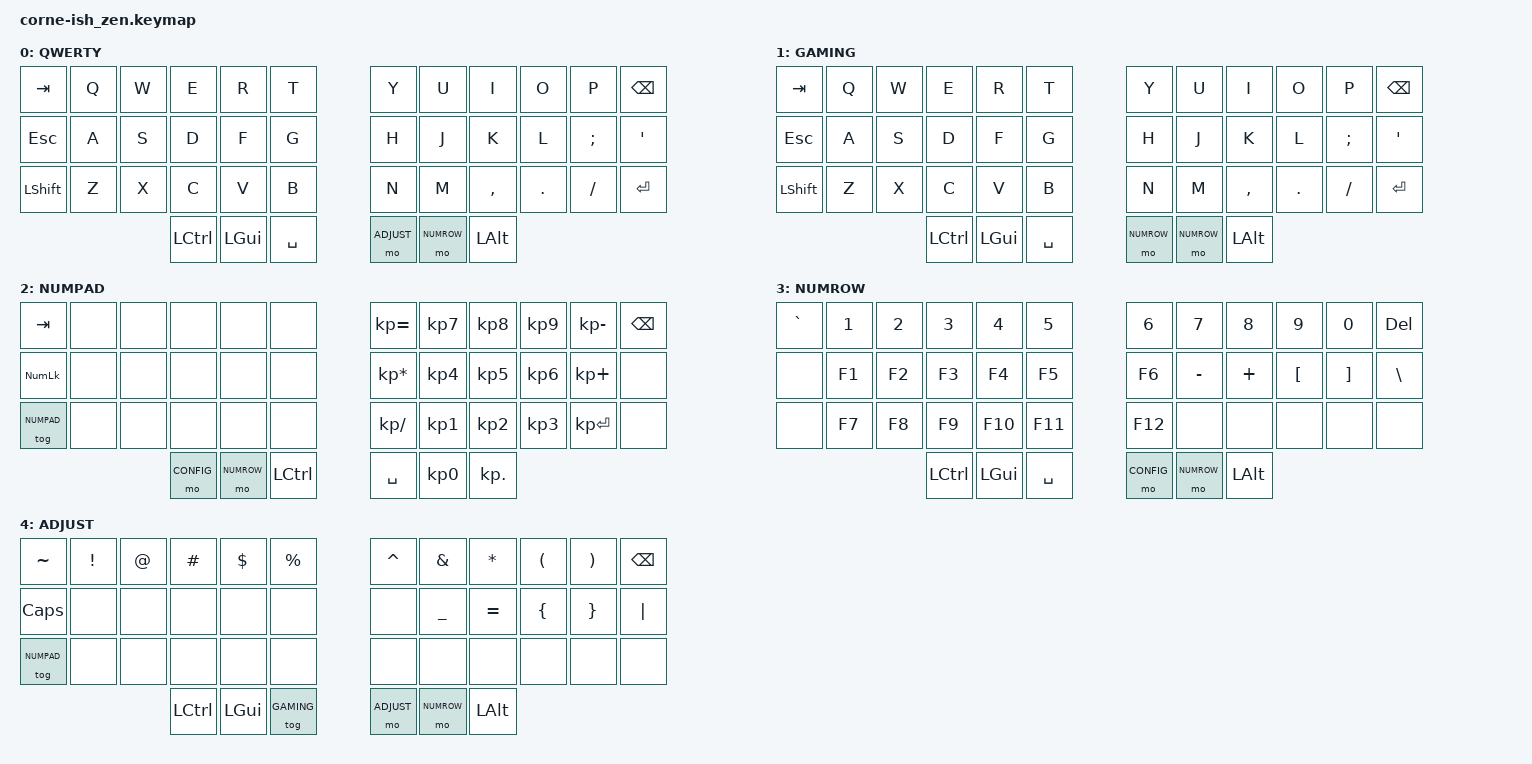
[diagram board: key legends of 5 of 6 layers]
/*
*
* Copyright (c) 2021 lowprokb.ca
* SPDX-License-Identifier: MIT
*
*/

#include <behaviors.dtsi>
#include <dt-bindings/zmk/keys.h>
#include <dt-bindings/zmk/bt.h>

#define QWERTY 0
#define GAMING 1
#define NUMPAD 2
#define NUMROW 3
#define ADJUST 4
#define CONFIG 5

/ {
        keymap {
                compatible = "zmk,keymap";

                default_layer {
                        label = "QWERTY";
                        bindings = <
   &kp TAB   &kp Q &kp W &kp E &kp R &kp T    &kp Y &kp U &kp I    &kp O   &kp P    &kp BKSP
   &kp ESC  &kp A &kp S &kp D &kp F &kp G    &kp H &kp J &kp K    &kp L   &kp SEMI &kp QUOT 
   &kp LSHFT &kp Z &kp X &kp C &kp V &kp B    &kp N &kp M &kp CMMA &kp DOT &kp FSLH &kp RETURN
              &kp LCTL &kp LGUI &kp SPC    &mo ADJUST &mo NUMROW &kp LALT
                        >;
                };

                gaming_layer {
                        label = "GAMING";
                        bindings = <
   &kp TAB   &kp Q &kp W &kp E &kp R &kp T    &kp Y &kp U &kp I    &kp O   &kp P    &kp BKSP
   &kp ESC  &kp A &kp S &kp D &kp F &kp G    &kp H &kp J &kp K    &kp L   &kp SEMI &kp QUOT 
   &kp LSHFT &kp Z &kp X &kp C &kp V &kp B    &kp N &kp M &kp CMMA &kp DOT &kp FSLH &kp RETURN
              &kp LCTL &kp LGUI &kp SPC    &mo NUMROW &mo NUMROW &kp LALT
                        >;
                };

                numpad_layer {
                        label = "NUMPAD";
                        bindings = < 
   &kp TAB     &none &none &none &none &none    &kp KP_EQUAL    &kp KP_N7 &kp KP_N8 &kp KP_N9 &kp KP_MINUS &kp BSPC
   &kp KP_NLCK &none &none &none &none &none    &kp KP_ASTERISK &kp KP_N4 &kp KP_N5 &kp KP_N6 &kp KP_PLUS  &none
   &tog NUMPAD &none &none &none &none &none    &kp KP_SLASH    &kp KP_N1 &kp KP_N2 &kp KP_N3 &kp KP_ENTER &none
              &mo CONFIG &mo NUMROW &kp LCTL   &kp SPC &kp KP_N0 &kp KP_DOT
                        >;
                };

                numrow_layer {
                        label = "NUMROW";
                        bindings = <
   &kp GRAVE &kp N1 &kp N2  &kp N3 &kp N4 &kp N5       &kp N6   &kp N7   &kp N8 &kp N9    &kp N0   &kp DEL
   &none     &kp F1  &kp F2 &kp F3 &kp F4 &kp F5    &kp F6 &kp MINUS &kp PLUS &kp LBKT &kp RBKT &kp BSLH
   &none     &kp F7  &kp F8 &kp F9 &kp F10  &kp F11     &kp F12    &none    &none  &none     &none    &none 
                          &kp LCTL &kp LGUI &kp SPACE    &mo CONFIG  &mo NUMROW &kp LALT

                        >;
                };

                adjust_layer {
                        label = "ADJUST";
                        bindings = <
   &kp TILDE   &kp EXCL  &kp AT   &kp POUND &kp DLLR &kp PRCNT    &kp CARET   &kp AMPS   &kp STAR &kp LPAR   &kp RPAR &kp BKSP
   &kp CAPS    &none  &none &none &none  &none     &none  &kp UNDER &kp EQUAL &kp LBRC &kp RBRC   &kp PIPE
   &tog NUMPAD &none &none &none &none  &none     &none    &none    &none  &none     &none   &none
                           &kp LCTL &kp LGUI &tog GAMING  &mo ADJUST &mo NUMROW &kp LALT
                        >;
                };

                config_layer {
                        label = "CONFIG";
                        bindings = <
   &reset     &none        &none        &none        &none        &none           &none &none &none &none &none &none 
   &bt BT_CLR &bt BT_SEL 0 &bt BT_SEL 1 &bt BT_SEL 2 &bt BT_SEL 3 &bt BT_SEL 4    &none &none &none &none &none &none
   &none             &none        &none        &none        &none           &none &none &none &none &none &none
                          &kp LCTL &kp LGUI &kp SPACE    &mo CONFIG  &mo NUMROW &kp LALT
                        >;
                };
        };
};
